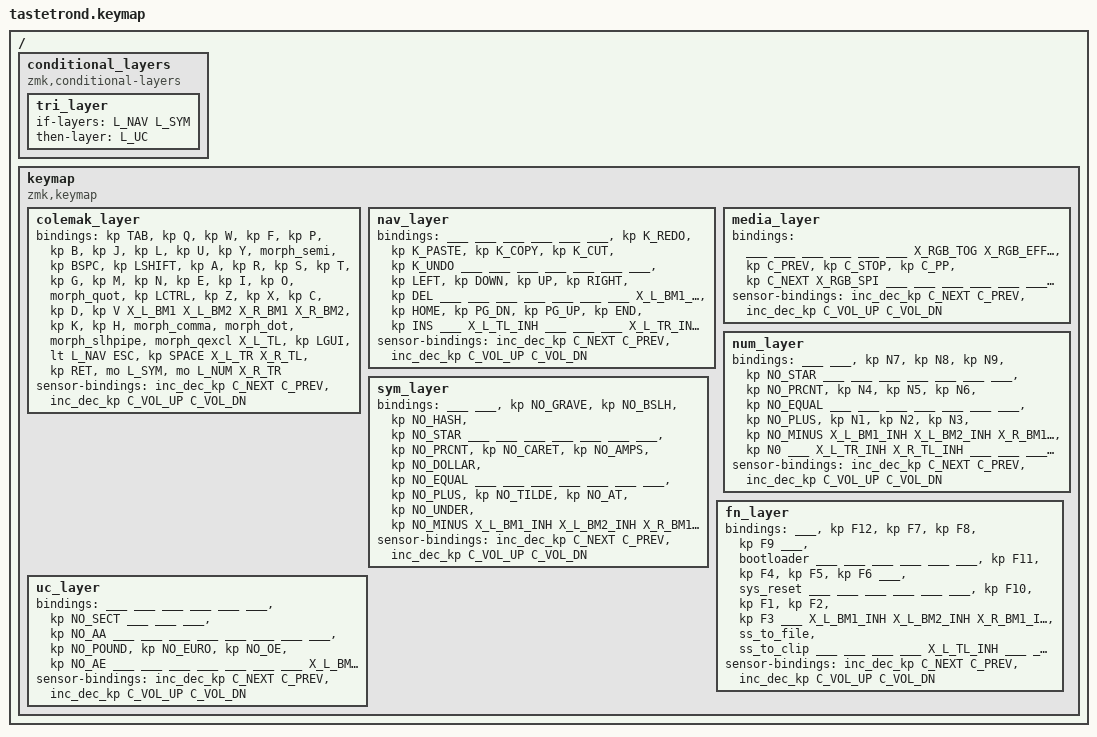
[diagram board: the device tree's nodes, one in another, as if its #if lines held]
// zmk
#include <behaviors.dtsi>
#include <dt-bindings/zmk/ext_power.h>
#include <dt-bindings/zmk/bt.h>
#include <dt-bindings/zmk/keys.h>
#include <dt-bindings/zmk/rgb.h>

// local config
#include "base.dtsi"
#include "norwegian.dtsi"
#include "behaviors.dtsi"
#include "combos.dtsi"
#include "macros.dtsi"

// default layout has 42 keys, additional keys can be set by defining any of these macros before including the keymap
#if defined X_L_BM1 // bottom row left half, extra middle button 1
    #define X_L_BM1_INH ___
#else
    #define X_L_BM1
    #define X_L_BM1_INH
#endif
#if defined X_L_BM2 // bottom row left half, extra middle button 2
    #define X_L_BM2_INH ___
#else
    #define X_L_BM2
    #define X_L_BM2_INH
#endif
#if defined X_R_BM1 // bottom row left right, extra middle button 1
    #define X_R_BM1_INH ___
#else
    #define X_R_BM1
    #define X_R_BM1_INH
#endif
#if defined X_R_BM2 // bottom row left right, extra middle button 2
    #define X_R_BM2_INH ___
#else
    #define X_R_BM2
    #define X_R_BM2_INH
#endif
#if defined X_L_TL // thumb row left half, left of the default thumb row keys
    #define X_L_TL_INH ___
#else
    #define X_L_TL
    #define X_L_TL_INH
#endif
#if defined X_L_TR // thumb row left half, right of the default thumb row keys
    #define X_L_TR_INH ___
#else
    #define X_L_TR
    #define X_L_TR_INH
#endif
#if defined X_R_TL // thumb row right half, left of the default thumb row keys
    #define X_R_TL_INH ___
#else
    #define X_R_TL
    #define X_R_TL_INH
#endif
#if defined X_R_TR // thumb row right half, right of the default thumb row keys
    #define X_R_TR_INH ___
#else
    #define X_R_TR
    #define X_R_TR_INH
#endif

// rgb support
#ifdef ENABLE_RGB_KEYS
    #define X_RGB_TOG &rgb_ug RGB_TOG
    #define X_RGB_EFF &rgb_ug RGB_EFF
    #define X_RGB_HUI &rgb_ug RGB_HUI
    #define X_RGB_SAI &rgb_ug RGB_SAI
    #define X_RGB_BRI &rgb_ug RGB_BRI
    #define X_RGB_BRD &rgb_ug RGB_BRD
    #define X_RGB_SPI &rgb_ug RGB_SPI
#else
    #define X_RGB_TOG ___
    #define X_RGB_EFF ___
    #define X_RGB_HUI ___
    #define X_RGB_SAI ___
    #define X_RGB_BRI ___
    #define X_RGB_BRD ___
    #define X_RGB_SPI ___
#endif

#ifdef ENABLE_BT_KEYS
    #define X_BT_SEL0 &bt BT_SEL 0
    #define X_BT_SEL1 &bt BT_SEL 1
    #define X_BT_SEL2 &bt BT_SEL 2
    #define X_BT_SEL3 &bt BT_SEL 3
    #define X_BT_CLR &bt BT_CLR
#else
    #define X_BT_SEL0 ___
    #define X_BT_SEL1 ___
    #define X_BT_SEL2 ___
    #define X_BT_SEL3 ___
    #define X_BT_CLR ___
#endif

/ {
  conditional_layers {
    compatible = "zmk,conditional-layers";
    tri_layer {
      if-layers = <L_NAV L_SYM>;
      then-layer = <L_UC>;
    };
  };

  keymap {
    compatible = "zmk,keymap";

    colemak_layer {
      bindings = <
        //╭───────────────┬───────────────┬───────────────┬───────────────┬───────────────┬───────────────╮                                                                     ╭───────────────┬───────────────┬───────────────┬───────────────┬───────────────┬───────────────╮
            &kp TAB         &kp Q           &kp W           &kp F           &kp P           &kp B                                                                                 &kp J           &kp L           &kp U           &kp Y           &morph_semi     &kp BSPC
        //├───────────────┼───────────────┼───────────────┼───────────────┼───────────────┤───────────────┤                                                                     ├───────────────┼───────────────┼───────────────┼───────────────┤───────────────┼───────────────┤
            &kp LSHIFT      &kp A           &kp R           &kp S           &kp T           &kp G                                                                                 &kp M           &kp N           &kp E           &kp I           &kp O           &morph_quot
        //├───────────────┼───────────────┼───────────────┼───────────────┼───────────────┤───────────────┤───────────────┬───────────────╮     ╭───────────────┬───────────────┼───────────────┼───────────────┼───────────────┼───────────────┤───────────────┼───────────────┤
            &kp LCTRL       &kp Z           &kp X           &kp C           &kp D           &kp V           X_L_BM1         X_L_BM2               X_R_BM1         X_R_BM2         &kp K           &kp H           &morph_comma    &morph_dot      &morph_slhpipe  &morph_qexcl
        //╰───────────────┴───────────────┴───────────────┼───────────────┼───────────────┤───────────────┤───────────────┤───────────────┤     ├───────────────┼───────────────┼───────────────┼───────────────┼───────────────┼───────────────┴───────────────┴───────────────╯
                                                            X_L_TL          &kp LGUI        &lt L_NAV ESC   &kp SPACE       X_L_TR                X_R_TL          &kp RET         &mo L_SYM       &mo L_NUM       X_R_TR
        //                                                ╰───────────────┴───────────────┴───────────────┴───────────────┴───────────────╯     ╰───────────────┴───────────────┴───────────────┴───────────────┴───────────────╯
      >;
#ifdef ENABLE_ENCODERS
      sensor-bindings = <&inc_dec_kp C_NEXT C_PREV &inc_dec_kp C_VOL_UP C_VOL_DN>;
#endif
    };

    nav_layer {
      bindings = <
        //╭───────────────┬───────────────┬───────────────┬───────────────┬───────────────┬───────────────╮                                                                     ╭───────────────┬───────────────┬───────────────┬───────────────┬───────────────┬───────────────╮
            ___             ___             ___             ___             ___             ___                                                                                   &kp K_REDO      &kp K_PASTE     &kp K_COPY      &kp K_CUT       &kp K_UNDO      ___
        //├───────────────┼───────────────┼───────────────┼───────────────┼───────────────┤───────────────┤                                                                     ├───────────────┼───────────────┼───────────────┼───────────────┤───────────────┼───────────────┤
            ___             ___             ___             ___             ___             ___                                                                                   &kp LEFT        &kp DOWN        &kp UP          &kp RIGHT       &kp DEL         ___
        //├───────────────┼───────────────┼───────────────┼───────────────┼───────────────┤───────────────┤───────────────┬───────────────╮     ╭───────────────┬───────────────┼───────────────┼───────────────┼───────────────┼───────────────┤───────────────┼───────────────┤
            ___             ___             ___             ___             ___             ___             X_L_BM1_INH     X_L_BM2_INH           X_R_BM1_INH     X_R_BM2_INH     &kp HOME        &kp PG_DN       &kp PG_UP       &kp END         &kp INS         ___
        //╰───────────────┴───────────────┴───────────────┼───────────────┼───────────────┤───────────────┤───────────────┤───────────────┤     ├───────────────┼───────────────┼───────────────┼───────────────┼───────────────┼───────────────┴───────────────┴───────────────╯
                                                            X_L_TL_INH      ___             ___             ___             X_L_TR_INH            X_R_TL_INH      ___             ___             ___             X_R_TR_INH
        //                                                ╰───────────────┴───────────────┴───────────────┴───────────────┴───────────────╯     ╰───────────────┴───────────────┴───────────────┴───────────────┴───────────────╯
      >;
#ifdef ENABLE_ENCODERS
      sensor-bindings = <&inc_dec_kp C_NEXT C_PREV &inc_dec_kp C_VOL_UP C_VOL_DN>;
#endif
    };

    media_layer {
      bindings = <
        //╭───────────────┬───────────────┬───────────────┬───────────────┬───────────────┬───────────────╮                                                                     ╭───────────────┬───────────────┬───────────────┬───────────────┬───────────────┬───────────────╮
            ___             ___             ___             ___             ___             ___                                                                                   X_RGB_TOG       X_RGB_EFF       X_RGB_HUI       X_RGB_SAI       X_RGB_BRI       X_RGB_BRD
        //├───────────────┼───────────────┼───────────────┼───────────────┼───────────────┤───────────────┤                                                                     ├───────────────┼───────────────┼───────────────┼───────────────┤───────────────┼───────────────┤
            ___             ___             ___             ___             ___             ___                                                                                   KP_EP_TOG       &kp C_PREV      &kp C_STOP      &kp C_PP        &kp C_NEXT      X_RGB_SPI
        //├───────────────┼───────────────┼───────────────┼───────────────┼───────────────┤───────────────┤───────────────┬───────────────╮     ╭───────────────┬───────────────┼───────────────┼───────────────┼───────────────┼───────────────┤───────────────┼───────────────┤
            ___             ___             ___             ___             ___             ___             X_L_BM1_INH     X_L_BM2_INH           X_R_BM1_INH     X_R_BM2_INH     X_BT_SEL0       X_BT_SEL1       X_BT_SEL2       X_BT_SEL3       X_BT_CLR        ___
        //╰───────────────┴───────────────┴───────────────┼───────────────┼───────────────┤───────────────┤───────────────┤───────────────┤     ├───────────────┼───────────────┼───────────────┼───────────────┼───────────────┼───────────────┴───────────────┴───────────────╯
                                                            X_L_TL_INH      ___             ___             ___             X_L_TR_INH            X_R_TL_INH      ___             ___             ___             X_R_TR_INH
        //                                                ╰───────────────┴───────────────┴───────────────┴───────────────┴───────────────╯     ╰───────────────┴───────────────┴───────────────┴───────────────┴───────────────╯
      >;
#ifdef ENABLE_ENCODERS
      sensor-bindings = <&inc_dec_kp C_NEXT C_PREV &inc_dec_kp C_VOL_UP C_VOL_DN>;
#endif
    };

    num_layer {
      bindings = <
        //╭───────────────┬───────────────┬───────────────┬───────────────┬───────────────┬───────────────╮                                                                     ╭───────────────┬───────────────┬───────────────┬───────────────┬───────────────┬───────────────╮
            ___             ___             &kp N7          &kp N8          &kp N9          &kp NO_STAR                                                                           ___             ___             ___             ___             ___             ___
        //├───────────────┼───────────────┼───────────────┼───────────────┼───────────────┤───────────────┤                                                                     ├───────────────┼───────────────┼───────────────┼───────────────┤───────────────┼───────────────┤
            ___             &kp NO_PRCNT    &kp N4          &kp N5          &kp N6          &kp NO_EQUAL                                                                          ___             ___             ___             ___             ___             ___
        //├───────────────┼───────────────┼───────────────┼───────────────┼───────────────┤───────────────┤───────────────┬───────────────╮     ╭───────────────┬───────────────┼───────────────┼───────────────┼───────────────┼───────────────┤───────────────┼───────────────┤
            ___             &kp NO_PLUS     &kp N1          &kp N2          &kp N3          &kp NO_MINUS    X_L_BM1_INH     X_L_BM2_INH           X_R_BM1_INH     X_R_BM2_INH     ___             ___             ___             ___             ___             ___
        //╰───────────────┴───────────────┴───────────────┼───────────────┼───────────────┤───────────────┤───────────────┤───────────────┤     ├───────────────┼───────────────┼───────────────┼───────────────┼───────────────┼───────────────┴───────────────┴───────────────╯
                                                            X_L_TL_INH      ___             &kp N0          ___             X_L_TR_INH            X_R_TL_INH      ___             ___             ___             X_R_TR_INH
        //                                                ╰───────────────┴───────────────┴───────────────┴───────────────┴───────────────╯     ╰───────────────┴───────────────┴───────────────┴───────────────┴───────────────╯
      >;
#ifdef ENABLE_ENCODERS
      sensor-bindings = <&inc_dec_kp C_NEXT C_PREV &inc_dec_kp C_VOL_UP C_VOL_DN>;
#endif
    };

    sym_layer {
      bindings = <
        //╭───────────────┬───────────────┬───────────────┬───────────────┬───────────────┬───────────────╮                                                                     ╭───────────────┬───────────────┬───────────────┬───────────────┬───────────────┬───────────────╮
            ___             ___             &kp NO_GRAVE    &kp NO_BSLH     &kp NO_HASH     &kp NO_STAR                                                                           ___             ___             ___             ___             ___             ___
        //├───────────────┼───────────────┼───────────────┼───────────────┼───────────────┤───────────────┤                                                                     ├───────────────┼───────────────┼───────────────┼───────────────┤───────────────┼───────────────┤
            ___             &kp NO_PRCNT    &kp NO_CARET    &kp NO_AMPS     &kp NO_DOLLAR   &kp NO_EQUAL                                                                          ___             ___             ___             ___             ___             ___
        //├───────────────┼───────────────┼───────────────┼───────────────┼───────────────┤───────────────┤───────────────┬───────────────╮     ╭───────────────┬───────────────┼───────────────┼───────────────┼───────────────┼───────────────┤───────────────┼───────────────┤
            ___             &kp NO_PLUS     &kp NO_TILDE    &kp NO_AT       &kp NO_UNDER    &kp NO_MINUS    X_L_BM1_INH     X_L_BM2_INH           X_R_BM1_INH     X_R_BM2_INH     ___             ___             ___             ___             ___             ___
        //╰───────────────┴───────────────┴───────────────┼───────────────┼───────────────┤───────────────┤───────────────┤───────────────┤     ├───────────────┼───────────────┼───────────────┼───────────────┼───────────────┼───────────────┴───────────────┴───────────────╯
                                                            X_L_TL_INH      ___             ___             ___             X_L_TR_INH            X_R_TL_INH      ___             ___             ___             X_R_TR_INH
        //                                                ╰───────────────┴───────────────┴───────────────┴───────────────┴───────────────╯     ╰───────────────┴───────────────┴───────────────┴───────────────┴───────────────╯
      >;
#ifdef ENABLE_ENCODERS
      sensor-bindings = <&inc_dec_kp C_NEXT C_PREV &inc_dec_kp C_VOL_UP C_VOL_DN>;
#endif
    };

    fn_layer {
      bindings = <
        //╭───────────────┬───────────────┬───────────────┬───────────────┬───────────────┬───────────────╮                                                                     ╭───────────────┬───────────────┬───────────────┬───────────────┬───────────────┬───────────────╮
            ___             &kp F12         &kp F7          &kp F8          &kp F9          ___                                                                                   &bootloader     ___             ___             ___             ___             ___
        //├───────────────┼───────────────┼───────────────┼───────────────┼───────────────┤───────────────┤                                                                     ├───────────────┼───────────────┼───────────────┼───────────────┤───────────────┼───────────────┤
            ___             &kp F11         &kp F4          &kp F5          &kp F6          ___                                                                                   &sys_reset      ___             ___             ___             ___             ___
        //├───────────────┼───────────────┼───────────────┼───────────────┼───────────────┤───────────────┤───────────────┬───────────────╮     ╭───────────────┬───────────────┼───────────────┼───────────────┼───────────────┼───────────────┤───────────────┼───────────────┤
            ___             &kp F10         &kp F1          &kp F2          &kp F3          ___             X_L_BM1_INH     X_L_BM2_INH           X_R_BM1_INH     X_R_BM2_INH     &ss_to_file     &ss_to_clip     ___             ___             ___             ___
        //╰───────────────┴───────────────┴───────────────┼───────────────┼───────────────┤───────────────┤───────────────┤───────────────┤     ├───────────────┼───────────────┼───────────────┼───────────────┼───────────────┼───────────────┴───────────────┴───────────────╯
                                                            X_L_TL_INH      ___             ___             ___             X_L_TR_INH            X_R_TL_INH      ___             ___             ___             X_R_TR
        //                                                ╰───────────────┴───────────────┴───────────────┴───────────────┴───────────────╯     ╰───────────────┴───────────────┴───────────────┴───────────────┴───────────────╯
      >;
#ifdef ENABLE_ENCODERS
      sensor-bindings = <&inc_dec_kp C_NEXT C_PREV &inc_dec_kp C_VOL_UP C_VOL_DN>;
#endif
    };

    uc_layer {
      bindings = <
        //╭───────────────┬───────────────┬───────────────┬───────────────┬───────────────┬───────────────╮                                                                     ╭───────────────┬───────────────┬───────────────┬───────────────┬───────────────┬───────────────╮
            ___             ___             ___             ___             ___             ___                                                                                   &kp NO_SECT     ___             ___             ___             &kp NO_AA       ___
        //├───────────────┼───────────────┼───────────────┼───────────────┼───────────────┤───────────────┤                                                                     ├───────────────┼───────────────┼───────────────┼───────────────┤───────────────┼───────────────┤
            ___             ___             ___             ___             ___             ___                                                                                   ___             &kp NO_POUND    &kp NO_EURO     &kp NO_OE       &kp NO_AE       ___
        //├───────────────┼───────────────┼───────────────┼───────────────┼───────────────┤───────────────┤───────────────┬───────────────╮     ╭───────────────┬───────────────┼───────────────┼───────────────┼───────────────┼───────────────┤───────────────┼───────────────┤
            ___             ___             ___             ___             ___             ___             X_L_BM1_INH     X_L_BM2_INH           X_R_BM1_INH     X_R_BM2_INH     ___             ___             ___             ___             ___             ___
        //╰───────────────┴───────────────┴───────────────┼───────────────┼───────────────┤───────────────┤───────────────┤───────────────┤     ├───────────────┼───────────────┼───────────────┼───────────────┼───────────────┼───────────────┴───────────────┴───────────────╯
                                                            X_L_TL_INH      ___             ___             ___             X_L_TR_INH            X_R_TL_INH      ___             ___             ___             X_R_TR_INH
        //                                                ╰───────────────┴───────────────┴───────────────┴───────────────┴───────────────╯     ╰───────────────┴───────────────┴───────────────┴───────────────┴───────────────╯
      >;
#ifdef ENABLE_ENCODERS
      sensor-bindings = <&inc_dec_kp C_NEXT C_PREV &inc_dec_kp C_VOL_UP C_VOL_DN>;
#endif
    };
  };
};
